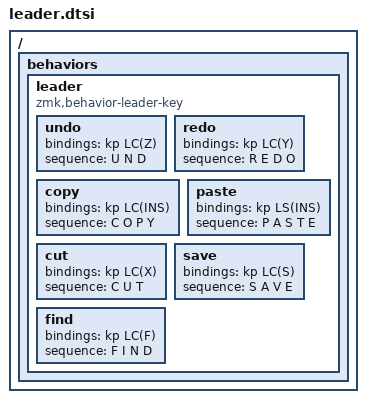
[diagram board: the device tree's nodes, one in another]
/* Leader key behavior using zmk-leader-key module */

/ {
    behaviors {
        // Define the leader key behavior
        leader: leader {
            compatible = "zmk,behavior-leader-key";
            #binding-cells = <0>;
            
            // Leader sequences
            undo: undo {
                bindings = <&kp LC(Z)>;
                sequence = <U N D>;
            };
            redo: redo {
                bindings = <&kp LC(Y)>;
                sequence = <R E D O>;
            };
            copy: copy {
                bindings = <&kp LC(INS)>;
                sequence = <C O P Y>;
            };
            paste: paste {
                bindings = <&kp LS(INS)>;
                sequence = <P A S T E>;
            };
            cut: cut {
                bindings = <&kp LC(X)>;
                sequence = <C U T>;
            };
            save: save {
                bindings = <&kp LC(S)>;
                sequence = <S A V E>;
            };
            find: find {
                bindings = <&kp LC(F)>;
                sequence = <F I N D>;
            };
        };
    };
};
